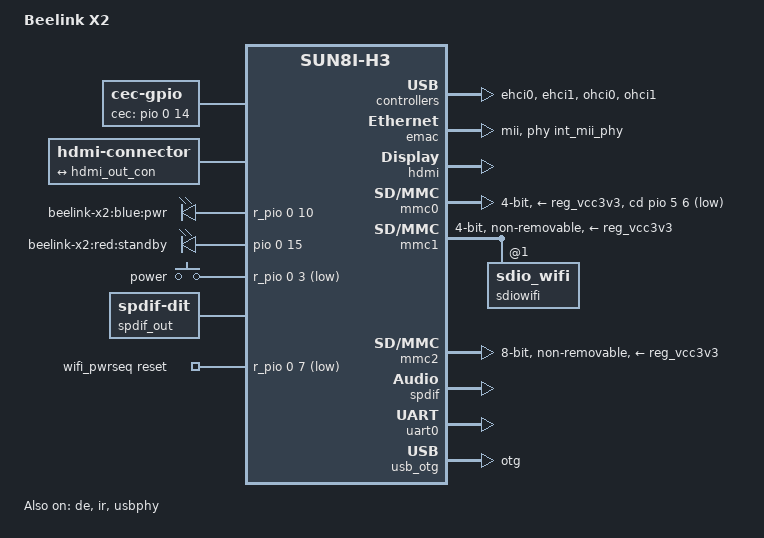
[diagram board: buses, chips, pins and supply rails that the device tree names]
/dts-v1/;
#include "sun8i-h3.dtsi"
#include "sunxi-common-regulators.dtsi"
#include <dt-bindings/gpio/gpio.h>
#include <dt-bindings/input/input.h>
/ {
	model = "Beelink X2";
	compatible = "roofull,beelink-x2", "allwinner,sun8i-h3";
	aliases {
		serial0 = &uart0;
		ethernet0 = &emac;
		ethernet1 = &sdiowifi;
	};
	cec {
		compatible = "cec-gpio";
		cec-gpios = <&pio 0 14 (GPIO_ACTIVE_HIGH|GPIO_OPEN_DRAIN)>;  
		hdmi-phandle = <&hdmi>;
	};
	chosen {
		stdout-path = "serial0:115200n8";
	};
	connector {
		compatible = "hdmi-connector";
		type = "a";
		port {
			hdmi_con_in: endpoint {
				remote-endpoint = <&hdmi_out_con>;
			};
		};
	};
	leds {
		compatible = "gpio-leds";
		led-0 {
			label = "beelink-x2:blue:pwr";
			gpios = <&r_pio 0 10 GPIO_ACTIVE_HIGH>;  
			default-state = "on";
		};
		led-1 {
			label = "beelink-x2:red:standby";
			gpios = <&pio 0 15 GPIO_ACTIVE_HIGH>;  
		};
	};
	gpio-keys {
		compatible = "gpio-keys";
		key-power {
			label = "power";
			linux,code = <KEY_POWER>;
			gpios = <&r_pio 0 3 GPIO_ACTIVE_LOW>;
			wakeup-source;
		};
	};
	sound_spdif {
		compatible = "simple-audio-card";
		simple-audio-card,name = "On-board SPDIF";
		simple-audio-card,cpu {
			sound-dai = <&spdif>;
		};
		simple-audio-card,codec {
			sound-dai = <&spdif_out>;
		};
	};
	spdif_out: spdif-out {
		#sound-dai-cells = <0>;
		compatible = "linux,spdif-dit";
	};
	wifi_pwrseq: wifi_pwrseq {
		compatible = "mmc-pwrseq-simple";
		reset-gpios = <&r_pio 0 7 GPIO_ACTIVE_LOW>;  
		clocks = <&rtc CLK_OSC32K_FANOUT>;
		clock-names = "ext_clock";
	};
};
&de {
	status = "okay";
};
&ehci0 {
	status = "okay";
};
&ehci1 {
	status = "okay";
};
&emac {
	phy-handle = <&int_mii_phy>;
	phy-mode = "mii";
	allwinner,leds-active-low;
	status = "okay";
};
&hdmi {
	status = "okay";
};
&hdmi_out {
	hdmi_out_con: endpoint {
		remote-endpoint = <&hdmi_con_in>;
	};
};
&ir {
	linux,rc-map-name = "rc-tanix-tx3mini";
	pinctrl-names = "default";
	pinctrl-0 = <&r_ir_rx_pin>;
	status = "okay";
};
&mmc0 {
	vmmc-supply = <&reg_vcc3v3>;
	bus-width = <4>;
	cd-gpios = <&pio 5 6 GPIO_ACTIVE_LOW>;  
	status = "okay";
};
&mmc1 {
	vmmc-supply = <&reg_vcc3v3>;
	vqmmc-supply = <&reg_vcc3v3>;
	mmc-pwrseq = <&wifi_pwrseq>;
	bus-width = <4>;
	non-removable;
	status = "okay";
	sdiowifi: sdio_wifi@1 {
		reg = <1>;
	};
};
&mmc2 {
	pinctrl-names = "default";
	pinctrl-0 = <&mmc2_8bit_pins>;
	vmmc-supply = <&reg_vcc3v3>;
	bus-width = <8>;
	non-removable;
	cap-mmc-hw-reset;
	status = "okay";
};
&ohci0 {
	status = "okay";
};
&ohci1 {
	status = "okay";
};
&reg_usb0_vbus {
	gpio = <&r_pio 0 2 GPIO_ACTIVE_HIGH>;  
	status = "okay";
};
&spdif {
	pinctrl-names = "default";
	pinctrl-0 = <&spdif_tx_pin>;
	status = "okay";
};
&uart0 {
	pinctrl-names = "default";
	pinctrl-0 = <&uart0_pa_pins>;
	status = "okay";
};
&usb_otg {
	dr_mode = "otg";
	status = "okay";
};
&usbphy {
	status = "okay";
	usb0_id_det-gpios = <&pio 0 7 GPIO_ACTIVE_HIGH>;  
	usb0_vbus-supply = <&reg_usb0_vbus>;
};
